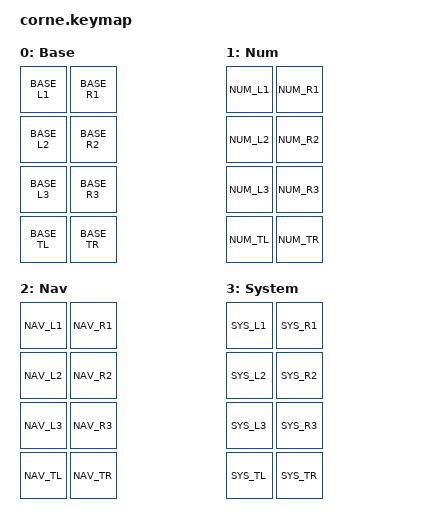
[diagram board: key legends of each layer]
// Ported from the Vial keymap in zvakanaka/vial-qmk (keyboards/crkbd/keymaps/vial).
// The behaviors and the layers' keys are shared with the other keyboards: config/common/.

// Key positions (3x5 + 3 thumbs):
//  0  1  2  3  4     5  6  7  8  9
// 10 11 12 13 14    15 16 17 18 19
// 20 21 22 23 24    25 26 27 28 29
//       30 31 32    33 34 35

#define HS_FOLLOW_POS 10                // A
#define HSP_FOLLOW_POS 29               // /
#define SYSTEM_COMBO_POSITIONS 34 35    // Enter and Backspace
#include "common/behaviors.dtsi"
#include "common/combos.dtsi"
#include "common/layers.dtsi"

/ {
    chosen {
        zmk,physical-layout = &foostan_corne_5col_layout;
    };

    keymap {
        compatible = "zmk,keymap";

        default_layer {
            display-name = "Base";
            bindings = <
BASE_L1  BASE_R1
BASE_L2  BASE_R2
BASE_L3  BASE_R3
         BASE_TL  BASE_TR
            >;
        };

        num {
            display-name = "Num";
            bindings = <
NUM_L1  NUM_R1
NUM_L2  NUM_R2
NUM_L3  NUM_R3
        NUM_TL  NUM_TR
            >;
        };

        nav {
            display-name = "Nav";
            bindings = <
NAV_L1  NAV_R1
NAV_L2  NAV_R2
NAV_L3  NAV_R3
        NAV_TL  NAV_TR
            >;
        };

        system {
            display-name = "System";
            bindings = <
SYS_L1  SYS_R1
SYS_L2  SYS_R2
SYS_L3  SYS_R3
        SYS_TL  SYS_TR
            >;
        };
    };
};
